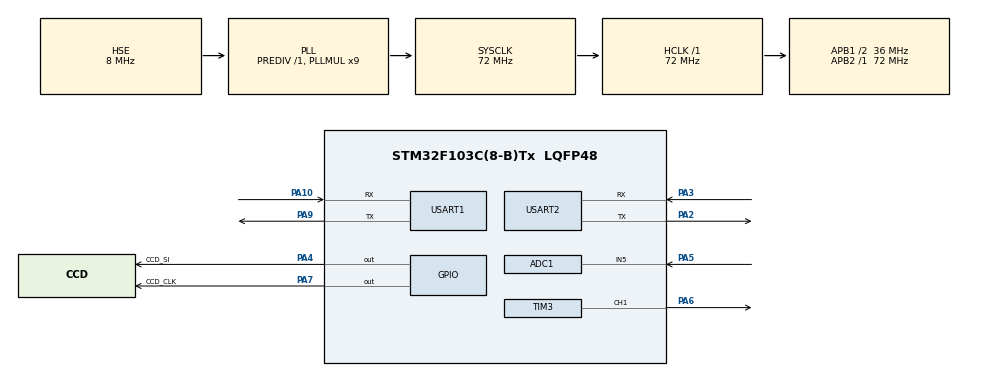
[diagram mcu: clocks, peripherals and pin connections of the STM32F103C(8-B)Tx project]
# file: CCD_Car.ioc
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ADC1.Channel-0\#ChannelRegularConversion=ADC_CHANNEL_5
ADC1.NbrOfConversion=1
ADC1.NbrOfConversionFlag=1
ADC1.Rank-0\#ChannelRegularConversion=1
ADC1.SamplingTime-0\#ChannelRegularConversion=ADC_SAMPLETIME_239CYCLES_5
ADC1.master=1
Mcu.Family=STM32F1
Mcu.Name=STM32F103C(8-B)Tx
Mcu.Package=LQFP48
NVIC.PriorityGroup=NVIC_PRIORITYGROUP_4
NVIC.TIM4_IRQn=true\:0\:0\:false\:false\:true\:true\:true\:true
PA10.Mode=Asynchronous
PA10.Signal=USART1_RX
PA13.Mode=Serial_Wire
PA13.Signal=SYS_JTMS-SWDIO
PA14.Mode=Serial_Wire
PA14.Signal=SYS_JTCK-SWCLK
PA2.Mode=Asynchronous
PA2.Signal=USART2_TX
PA3.Mode=Asynchronous
PA3.Signal=USART2_RX
PA4.GPIO_Label=CCD_SI
PA4.GPIO_PuPd=GPIO_PULLUP
PA4.GPIO_Speed=GPIO_SPEED_FREQ_HIGH
PA4.PinState=GPIO_PIN_SET
PA4.Signal=GPIO_Output
PA5.Signal=ADCx_IN5
PA6.Signal=S_TIM3_CH1
PA7.GPIO_Label=CCD_CLK
PA7.GPIO_PuPd=GPIO_PULLUP
PA7.GPIO_Speed=GPIO_SPEED_FREQ_HIGH
PA7.PinState=GPIO_PIN_SET
PA7.Signal=GPIO_Output
PA9.Mode=Asynchronous
PA9.Signal=USART1_TX
PD0-OSC_IN.Mode=HSE-External-Oscillator
PD0-OSC_IN.Signal=RCC_OSC_IN
PD1-OSC_OUT.Mode=HSE-External-Oscillator
PD1-OSC_OUT.Signal=RCC_OSC_OUT
ProjectManager.HeapSize=0x200
ProjectManager.StackSize=0x400
ProjectManager.TargetToolchain=STM32CubeIDE
RCC.ADCPresc=RCC_ADCPCLK2_DIV6
RCC.AHBFreq_Value=72000000
RCC.APB1CLKDivider=RCC_HCLK_DIV2
RCC.APB1Freq_Value=36000000
RCC.APB1TimFreq_Value=72000000
RCC.APB2Freq_Value=72000000
RCC.APB2TimFreq_Value=72000000
RCC.HCLKFreq_Value=72000000
RCC.PLLMUL=RCC_PLL_MUL9
RCC.PLLSourceVirtual=RCC_PLLSOURCE_HSE
RCC.SYSCLKFreq_VALUE=72000000
RCC.SYSCLKSource=RCC_SYSCLKSOURCE_PLLCLK
RCC.USBFreq_Value=72000000
SH.ADCx_IN5.0=ADC1_IN5,IN5
SH.S_TIM3_CH1.0=TIM3_CH1,PWM Generation1 CH1
TIM3.AutoReloadPreload=TIM_AUTORELOAD_PRELOAD_ENABLE
TIM3.Channel-PWM\ Generation1\ CH1=TIM_CHANNEL_1
TIM3.Period=2000-1
TIM3.Prescaler=720-1
TIM3.Pulse-PWM\ Generation1\ CH1=150
TIM4.AutoReloadPreload=TIM_AUTORELOAD_PRELOAD_ENABLE
TIM4.Period=9999
TIM4.Prescaler=72-1
USART1.VirtualMode=VM_ASYNC
USART2.VirtualMode=VM_ASYNC
VP_TIM3_VS_ClockSourceINT.Mode=Internal
VP_TIM4_VS_ClockSourceINT.Mode=Internal
board=custom

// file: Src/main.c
/* USER CODE BEGIN Header */
/**
  ******************************************************************************
  * @file           : main.c
  * @brief          : Main program body
  ******************************************************************************
  * @attention
  *
  * Copyright (c) 2023 STMicroelectronics.
  * All rights reserved.
  *
  * This software is licensed under terms that can be found in the LICENSE file
  * in the root directory of this software component.
  * If no LICENSE file comes with this software, it is provided AS-IS.
  *
  ******************************************************************************
  */
/* USER CODE END Header */
#include "main.h"
#include "adc.h"
#include "tim.h"
#include "usart.h"
#include "gpio.h"

/* USER CODE BEGIN Includes */
#include "PID.h"
#include "Motor.h"
/* USER CODE END Includes */

/* USER CODE BEGIN PV */
PID_struct Server_pid;
PID_struct Motor1_pid;
PID_struct Motor2_pid;
/* USER CODE END PV */

void SystemClock_Config(void);

int main(void)
{

  /* MCU Configuration--------------------------------------------------------*/

  /* Reset of all peripherals, Initializes the Flash interface and the Systick. */
  HAL_Init();

  /* Configure the system clock */
  SystemClock_Config();

  /* Initialize all configured peripherals */
  MX_GPIO_Init();
  MX_ADC1_Init();
  MX_TIM4_Init();
  MX_USART1_UART_Init();
  MX_TIM3_Init();
  MX_USART2_UART_Init();
  /* USER CODE BEGIN 2 */
  HAL_TIM_Base_Start_IT(&htim4);
  HAL_TIM_PWM_Start(&htim3,TIM_CHANNEL_1);

  PID_Init(&Server_pid,60,-3.0,0.000001,0.01);

  Zx_MotorRunS(1,120);
  Zx_MotorRunN(2,120);

  /* USER CODE END 2 */

  /* Infinite loop */
  while (1)
  {

  }
}

void SystemClock_Config(void)
{
  RCC_OscInitTypeDef RCC_OscInitStruct = {0};
  RCC_ClkInitTypeDef RCC_ClkInitStruct = {0};
  RCC_PeriphCLKInitTypeDef PeriphClkInit = {0};

  /** Initializes the RCC Oscillators according to the specified parameters
  * in the RCC_OscInitTypeDef structure.
  */
  RCC_OscInitStruct.OscillatorType = RCC_OSCILLATORTYPE_HSE;
  RCC_OscInitStruct.HSEState = RCC_HSE_ON;
  RCC_OscInitStruct.HSEPredivValue = RCC_HSE_PREDIV_DIV1;
  RCC_OscInitStruct.HSIState = RCC_HSI_ON;
  RCC_OscInitStruct.PLL.PLLState = RCC_PLL_ON;
  RCC_OscInitStruct.PLL.PLLSource = RCC_PLLSOURCE_HSE;
  RCC_OscInitStruct.PLL.PLLMUL = RCC_PLL_MUL9;
  if (HAL_RCC_OscConfig(&RCC_OscInitStruct) != HAL_OK)
  {
    Error_Handler();
  }

  /** Initializes the CPU, AHB and APB buses clocks
  */
  RCC_ClkInitStruct.ClockType = RCC_CLOCKTYPE_HCLK|RCC_CLOCKTYPE_SYSCLK
                              |RCC_CLOCKTYPE_PCLK1|RCC_CLOCKTYPE_PCLK2;
  RCC_ClkInitStruct.SYSCLKSource = RCC_SYSCLKSOURCE_PLLCLK;
  RCC_ClkInitStruct.AHBCLKDivider = RCC_SYSCLK_DIV1;
  RCC_ClkInitStruct.APB1CLKDivider = RCC_HCLK_DIV2;
  RCC_ClkInitStruct.APB2CLKDivider = RCC_HCLK_DIV1;

  if (HAL_RCC_ClockConfig(&RCC_ClkInitStruct, FLASH_LATENCY_2) != HAL_OK)
  {
    Error_Handler();
  }
  PeriphClkInit.PeriphClockSelection = RCC_PERIPHCLK_ADC;
  PeriphClkInit.AdcClockSelection = RCC_ADCPCLK2_DIV6;
  if (HAL_RCCEx_PeriphCLKConfig(&PeriphClkInit) != HAL_OK)
  {
    Error_Handler();
  }
}

void Error_Handler(void)
{
  __disable_irq();
  while (1)
  {
  }
}
